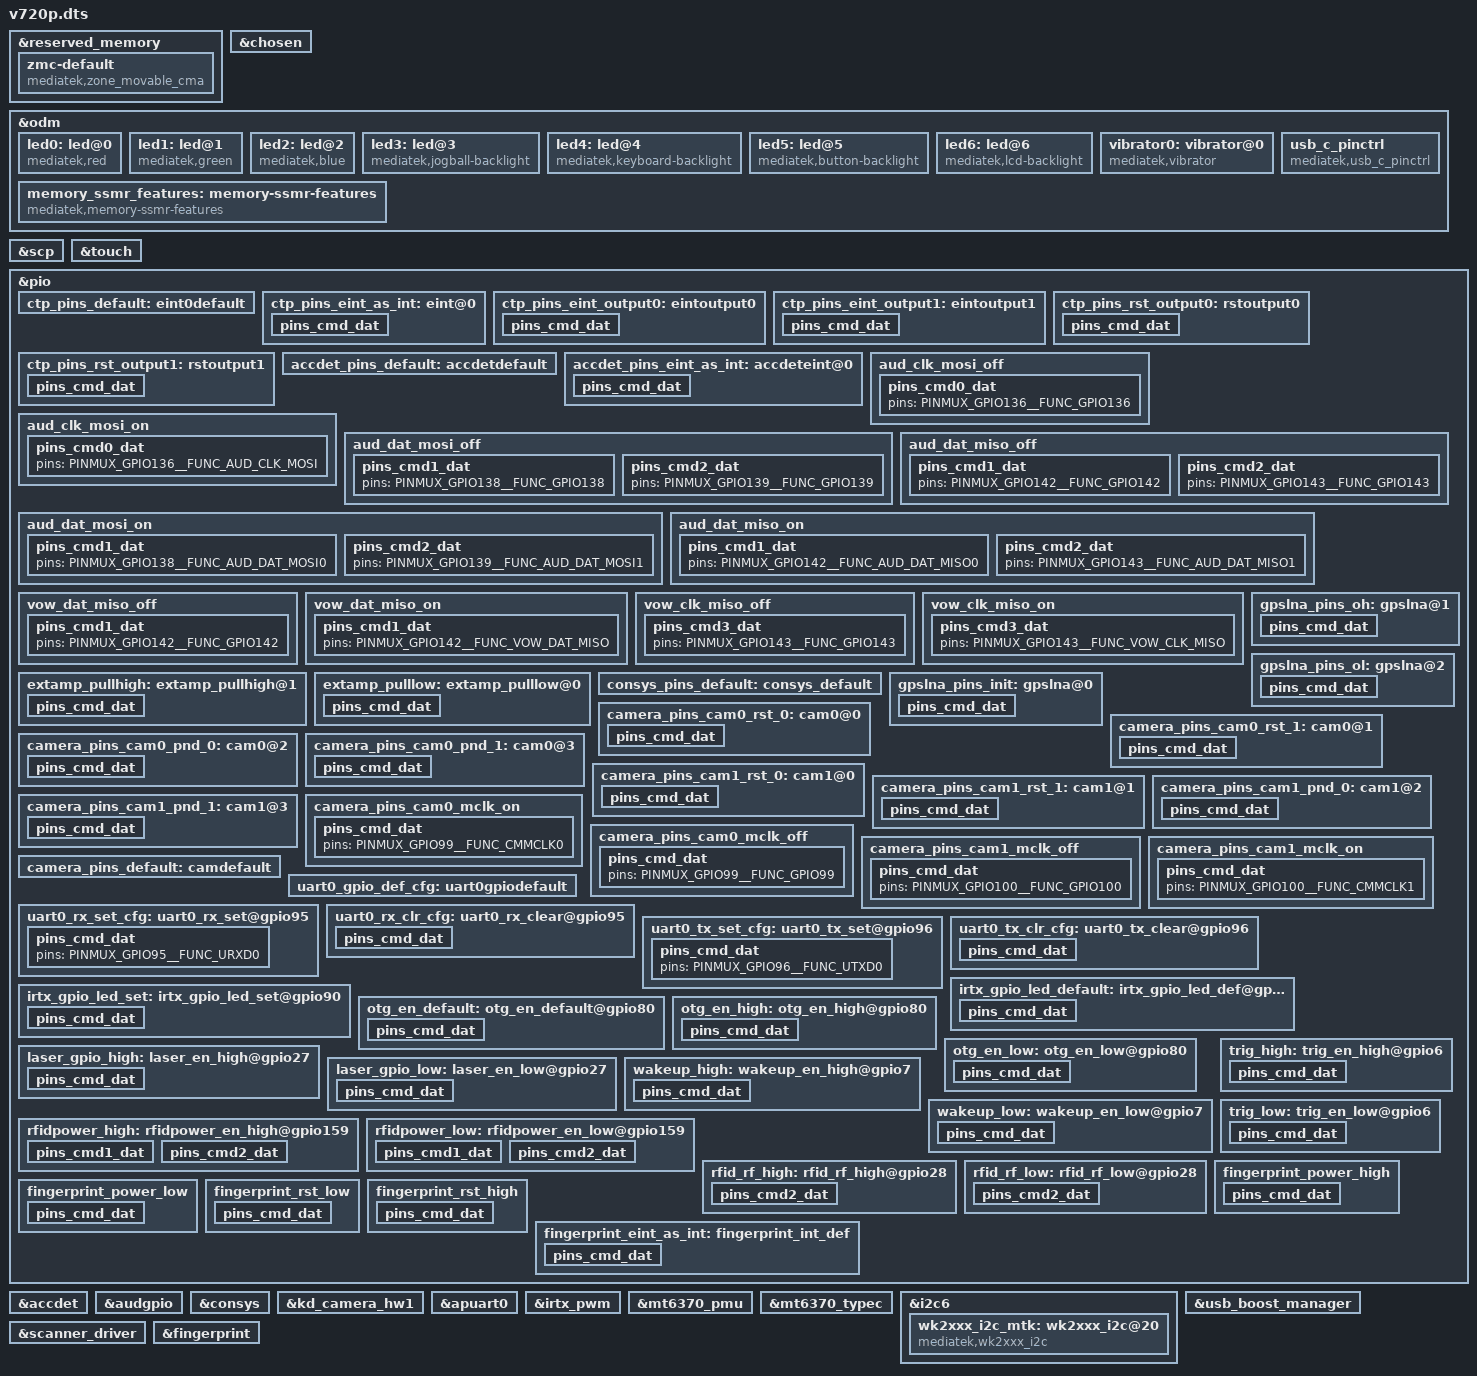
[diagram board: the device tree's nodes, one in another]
/dts-v1/;
/plugin/;
#include <dt-bindings/interrupt-controller/irq.h>
#include <dt-bindings/interrupt-controller/arm-gic.h>
#include <dt-bindings/pinctrl/mt6771-pinfunc.h>

&reserved_memory {
	#address-cells = <2>;
	#size-cells = <2>;
	ranges;

	zmc-default {
		compatible = "mediatek,zone_movable_cma";
		size = <0 0xffc00000>;
		alignment = <0 0x10000000>;
		alloc-ranges = <0 0xc0000000 1 0x00000000>;
	};
};

/* chosen */
&chosen {
	/* fpga may has no lk, we need to specify display info here */
	/* fb buffer is reserved using this dts by memory node above */

	atag,videolfb-fb_base_l = <0x5e605000>;
	atag,videolfb-fb_base_h = <0x0>;
	atag,videolfb-islcmfound = <1>;
	atag,videolfb-islcm_inited = <0>;
	atag,videolfb-fps= <6000>;
	atag,videolfb-vramSize= <0x017bb000>;
	atag,videolfb-lcmname= "nt35595_fhd_dsi_cmd_truly_nt50358_drv";
};

&odm {
	led0:led@0 {
		compatible = "mediatek,red";
		led_mode = <0>;
		data = <1>;
		pwm_config = <0 0 0 0 0>;
	};
	led1:led@1 {
		compatible = "mediatek,green";
		led_mode = <0>;
		data = <1>;
		pwm_config = <0 0 0 0 0>;
	};
	led2:led@2 {
		compatible = "mediatek,blue";
		led_mode = <0>;
		data = <1>;
		pwm_config = <0 0 0 0 0>;
	};
	led3:led@3 {
		compatible = "mediatek,jogball-backlight";
		led_mode = <0>;
		data = <1>;
		pwm_config = <0 0 0 0 0>;
	};
	led4:led@4 {
		compatible = "mediatek,keyboard-backlight";
		led_mode = <0>;
		data = <1>;
		pwm_config = <0 0 0 0 0>;
	};
	led5:led@5 {
		compatible = "mediatek,button-backlight";
		led_mode = <0>;
		data = <1>;
		pwm_config = <0 0 0 0 0>;
	};
	led6:led@6 {
		compatible = "mediatek,lcd-backlight";
		led_mode = <5>;
		data = <1>;
		pwm_config = <0 1 0 0 0>;
	};
	vibrator0:vibrator@0 {
		compatible = "mediatek,vibrator";
		vib_timer = <25>;
		vib_limit = <9>;
		vib_vol= <9>;
	};
	memory_ssmr_features: memory-ssmr-features {
		compatible = "mediatek,memory-ssmr-features";
		svp-size = <0 0>;
		iris-recognition-size = <0 0>;
		2d_fr-size = <0 0>;
		tui-size = <0 0>;
		wfd-size = <0 0>;
		prot-sharedmem-size = <0 0>;
	};
	usb_c_pinctrl:usb_c_pinctrl {
		compatible = "mediatek,usb_c_pinctrl";
	};
};

&scp {
	core_1 = "enable";
	scp_sramSize = <0x00080000>;     /* scp_A_sram_size */
};

/* TOUCH start */
&touch {
	tpd-resolution = <1080 1920>;
	use-tpd-button = <0>;
	tpd-key-num = <3>;
	tpd-key-local= <139 172 158 0>;
	tpd-key-dim-local = <90 883 100 40 230 883 100 40 370 883 100 40 0 0 0 0>;
	tpd-max-touch-num = <5>;
	tpd-filter-enable = <1>;
	tpd-filter-pixel-density = <146>;
	tpd-filter-custom-prameters = <0 0 0 0 0 0 0 0 0 0 0 0>;
	tpd-filter-custom-speed = <0 0 0>;
	pinctrl-names = "default", "state_eint_as_int", "state_eint_output0", "state_eint_output1",
		"state_rst_output0", "state_rst_output1";
	pinctrl-0 = <&ctp_pins_default>;
	pinctrl-1 = <&ctp_pins_eint_as_int>;
	pinctrl-2 = <&ctp_pins_eint_output0>;
	pinctrl-3 = <&ctp_pins_eint_output1>;
	pinctrl-4 = <&ctp_pins_rst_output0>;
	pinctrl-5 = <&ctp_pins_rst_output1>;
	status = "okay";
};
&pio {
	ctp_pins_default: eint0default {
	};
	ctp_pins_eint_as_int: eint@0 {
		pins_cmd_dat {
			pins = <PINMUX_GPIO1__FUNC_GPIO1>;
			slew-rate = <0>;
			bias-disable;
		};
	};
	ctp_pins_eint_output0: eintoutput0 {
		pins_cmd_dat {
			pins = <PINMUX_GPIO1__FUNC_GPIO1>;
			slew-rate = <1>;
			output-low;
		};
	};
	ctp_pins_eint_output1: eintoutput1 {
		pins_cmd_dat {
			pins = <PINMUX_GPIO1__FUNC_GPIO1>;
			slew-rate = <1>;
			output-high;
		};
	};
	ctp_pins_rst_output0: rstoutput0 {
		pins_cmd_dat {
			pins = <PINMUX_GPIO20__FUNC_GPIO20>;
			slew-rate = <1>;
			output-low;
		};
	};
	ctp_pins_rst_output1: rstoutput1 {
		pins_cmd_dat {
			pins = <PINMUX_GPIO20__FUNC_GPIO20>;
			slew-rate = <1>;
			output-high;
		};
	};
};
/* TOUCH end */

/* accdet start */
&accdet {
	/* accdet micbias voltage: 0x07,2.7v;0x05,2.5v;0x02,1.9v */
	accdet-mic-vol = <6>;
	headset-mode-setting = <0x500 0x500 1 0x1f0 0x800 0x800 0x20 0x44>;
	accdet-plugout-debounce = <1>;
	/*1:ACC mode, 2:low cost without in bias, 6:low cost with in bias*/
	accdet-mic-mode = <2>;
	/* eint_level_trigger: 8,LEVEL_LOW(default);4,LEVEL_HIGH;others,LEVEL_LOW */
	headset-eint-level-pol = <8>;
	/*0--MD_MAX--UP_MAX--DW_MAX*/
	headset-three-key-threshold = <0 60 200 400>;
	headset-three-key-threshold-CDD = <0 121 192 600>;
	/*0--MD_MAX--VOICE_MAX--UP_MAX--DW_MAX*/
	headset-four-key-threshold = <0 58 121 192 400>;
	/*moisture external resister ohm*/
	moisture-external-r = <2000000>;
	/*moisture internal resister ohm*/
	moisture-internal-r = <47000>;
	/*moisture of water resister ohm*/
	moisture-water-r = <10000>;
	/* ACCDET GPIO standardization ACC mode no use */
	pinctrl-names = "default", "state_eint_as_int";
	pinctrl-0 = <&accdet_pins_default>;
	pinctrl-1 = <&accdet_pins_eint_as_int>;
	status = "okay";
};
&pio {
	accdet_pins_default: accdetdefault {
	};
	accdet_pins_eint_as_int: accdeteint@0 {
		pins_cmd_dat {
		};
	};
};
/* accdet end */

/* AUDIO GPIO standardization */
&audgpio {
	pinctrl-names = "aud_clk_mosi_off",
			"aud_clk_mosi_on",
			"aud_dat_mosi_off",
			"aud_dat_mosi_on",
			"aud_dat_miso_off",
			"aud_dat_miso_on",
			"vow_dat_miso_off",
			"vow_dat_miso_on",
			"vow_clk_miso_off",
			"vow_clk_miso_on",
            "extamp-pullhigh",
            "extamp-pulllow";
	pinctrl-0 = <&aud_clk_mosi_off>;
	pinctrl-1 = <&aud_clk_mosi_on>;
	pinctrl-2 = <&aud_dat_mosi_off>;
	pinctrl-3 = <&aud_dat_mosi_on>;
	pinctrl-4 = <&aud_dat_miso_off>;
	pinctrl-5 = <&aud_dat_miso_on>;
	pinctrl-6 = <&vow_dat_miso_off>;
	pinctrl-7 = <&vow_dat_miso_on>;
	pinctrl-8 = <&vow_clk_miso_off>;
	pinctrl-9 = <&vow_clk_miso_on>;
	pinctrl-10 = <&extamp_pullhigh>;
	pinctrl-11 = <&extamp_pulllow>;
	status = "okay";
};

&pio {
	aud_clk_mosi_off: aud_clk_mosi_off {
		pins_cmd0_dat {
			pins = <PINMUX_GPIO136__FUNC_GPIO136>;
		};
	};

	aud_clk_mosi_on: aud_clk_mosi_on {
		pins_cmd0_dat {
			pins = <PINMUX_GPIO136__FUNC_AUD_CLK_MOSI>;
		};
	};

	aud_dat_mosi_off: aud_dat_mosi_off {
		pins_cmd1_dat {
			pins = <PINMUX_GPIO138__FUNC_GPIO138>;
		};
		pins_cmd2_dat {
			pins = <PINMUX_GPIO139__FUNC_GPIO139>;
		};
	};

	aud_dat_mosi_on: aud_dat_mosi_on {
		pins_cmd1_dat {
			pins = <PINMUX_GPIO138__FUNC_AUD_DAT_MOSI0>;
		};
		pins_cmd2_dat {
			pins = <PINMUX_GPIO139__FUNC_AUD_DAT_MOSI1>;
		};
	};

	aud_dat_miso_off: aud_dat_miso_off {
		pins_cmd1_dat {
			pins = <PINMUX_GPIO142__FUNC_GPIO142>;
		};
		pins_cmd2_dat {
			pins = <PINMUX_GPIO143__FUNC_GPIO143>;
		};
	};

	aud_dat_miso_on: aud_dat_miso_on {
		pins_cmd1_dat {
			pins = <PINMUX_GPIO142__FUNC_AUD_DAT_MISO0>;
		};
		pins_cmd2_dat {
			pins = <PINMUX_GPIO143__FUNC_AUD_DAT_MISO1>;
		};
	};

	vow_dat_miso_off: vow_dat_miso_off {
		pins_cmd1_dat {
			pins = <PINMUX_GPIO142__FUNC_GPIO142>;
		};
	};

	vow_dat_miso_on: vow_dat_miso_on {
		pins_cmd1_dat {
			pins = <PINMUX_GPIO142__FUNC_VOW_DAT_MISO>;
		};
	};

	vow_clk_miso_off: vow_clk_miso_off {
		pins_cmd3_dat {
			pins = <PINMUX_GPIO143__FUNC_GPIO143>;
		};
	};

	vow_clk_miso_on: vow_clk_miso_on {
		pins_cmd3_dat {
			pins = <PINMUX_GPIO143__FUNC_VOW_CLK_MISO>;
		};
	};
	extamp_pullhigh: extamp_pullhigh@1 {
		pins_cmd_dat {
			pins = <PINMUX_GPIO153__FUNC_GPIO153>;
			slew-rate = <1>;
			output-high;
		};
	};
	extamp_pulllow: extamp_pulllow@0 {
		pins_cmd_dat {
			pins = <PINMUX_GPIO153__FUNC_GPIO153>;
			slew-rate = <1>;
			output-low;
		};
	};
};
/* AUDIO end */

/* CONSYS GPIO standardization */
&pio {
	consys_pins_default: consys_default {
	};
	gpslna_pins_init: gpslna@0 {
		pins_cmd_dat {
			pins = <PINMUX_GPIO155__FUNC_GPIO155>;
			slew-rate = <0>;
			bias-disable;
			output-low;
		};
	};
	gpslna_pins_oh: gpslna@1 {
		pins_cmd_dat {
			pins = <PINMUX_GPIO155__FUNC_GPIO155>;
			slew-rate = <1>;
			output-high;
		};
	};
	gpslna_pins_ol: gpslna@2 {
		pins_cmd_dat {
			pins = <PINMUX_GPIO155__FUNC_GPIO155>;
			slew-rate = <1>;
			output-low;
		};
	};
};
&consys {
	pinctrl-names = "default", "gps_lna_state_init", "gps_lna_state_oh", "gps_lna_state_ol";
	pinctrl-0 = <&consys_pins_default>;
	pinctrl-1 = <&gpslna_pins_init>;
	pinctrl-2 = <&gpslna_pins_oh>;
	pinctrl-3 = <&gpslna_pins_ol>;
	status = "okay";
};
/* CONSYS end */

/* CAMERA GPIO standardization */
&pio {
	camera_pins_cam0_rst_0: cam0@0 {
		pins_cmd_dat {
			pins = <PINMUX_GPIO101__FUNC_GPIO101>;
			slew-rate = <1>; /*direction 0:in, 1:out*/
			output-low;/*direction out used only. output_low or high*/
		};
	};
	camera_pins_cam0_rst_1: cam0@1 {
		pins_cmd_dat {
			pins = <PINMUX_GPIO101__FUNC_GPIO101>;
			slew-rate = <1>;
			output-high;
		};
	};
	camera_pins_cam0_pnd_0: cam0@2 {
		pins_cmd_dat {
			pins = <PINMUX_GPIO97__FUNC_GPIO97>;
			slew-rate = <1>;
			output-low;
		};
	};
	camera_pins_cam0_pnd_1: cam0@3 {
		pins_cmd_dat {
			pins = <PINMUX_GPIO97__FUNC_GPIO97>;
			slew-rate = <1>;
			output-high;
		};
	};
	camera_pins_cam1_rst_0: cam1@0 {
		pins_cmd_dat {
			pins = <PINMUX_GPIO102__FUNC_GPIO102>;
			slew-rate = <1>; /*direction 0:in, 1:out*/
			output-low;/*direction out used only. output_low or high*/
		};
	};
	camera_pins_cam1_rst_1: cam1@1 {
		pins_cmd_dat {
			pins = <PINMUX_GPIO102__FUNC_GPIO102>;
			slew-rate = <1>;
			output-high;
		};
	};
	camera_pins_cam1_pnd_0: cam1@2 {
		pins_cmd_dat {
			pins = <PINMUX_GPIO98__FUNC_GPIO98>;
			slew-rate = <1>;
			output-low;
		};
	};
	camera_pins_cam1_pnd_1: cam1@3 {
		pins_cmd_dat {
			pins = <PINMUX_GPIO98__FUNC_GPIO98>;
			slew-rate = <1>;
			output-high;
		};
	};
	camera_pins_cam0_mclk_on: camera_pins_cam0_mclk_on {
		pins_cmd_dat {
			pins = <PINMUX_GPIO99__FUNC_CMMCLK0>;
		};
	};
	camera_pins_cam0_mclk_off: camera_pins_cam0_mclk_off {
		pins_cmd_dat {
			pins = <PINMUX_GPIO99__FUNC_GPIO99>;
		};
	};
	camera_pins_cam1_mclk_off: camera_pins_cam1_mclk_off {
		pins_cmd_dat {
			pins = <PINMUX_GPIO100__FUNC_GPIO100>;
		};
	};
	camera_pins_cam1_mclk_on: camera_pins_cam1_mclk_on {
		pins_cmd_dat {
			pins = <PINMUX_GPIO100__FUNC_CMMCLK1>;
		};
	};
	camera_pins_default: camdefault {
	};
};
&kd_camera_hw1 {
	pinctrl-names = "default",
			"cam0_rst0", "cam0_rst1",
			"cam0_pnd0", "cam0_pnd1",
			"cam1_rst0", "cam1_rst1",
			"cam1_pnd0", "cam1_pnd1",
			"cam0_mclk_off", "cam0_mclk_on",
			"cam1_mclk_off", "cam1_mclk_on";
	pinctrl-0 = <&camera_pins_default>;
	pinctrl-1 = <&camera_pins_cam0_rst_0>;
	pinctrl-2 = <&camera_pins_cam0_rst_1>;
	pinctrl-3 = <&camera_pins_cam0_pnd_0>;
	pinctrl-4 = <&camera_pins_cam0_pnd_1>;
	pinctrl-5 = <&camera_pins_cam1_rst_0>;
	pinctrl-6 = <&camera_pins_cam1_rst_1>;
	pinctrl-7 = <&camera_pins_cam1_pnd_0>;
	pinctrl-8 = <&camera_pins_cam1_pnd_1>;
	pinctrl-9 = <&camera_pins_cam0_mclk_off>;
	pinctrl-10 = <&camera_pins_cam0_mclk_on>;
	pinctrl-11 = <&camera_pins_cam1_mclk_off>;
	pinctrl-12 = <&camera_pins_cam1_mclk_on>;
	status = "okay";
};

/* UART GPIO */
&apuart0 {
	pinctrl-names = "uart0_gpio_default",
			"uart0_rx_set",
			"uart0_rx_clear",
			"uart0_tx_set",
			"uart0_tx_clear";
	pinctrl-0 = <&uart0_gpio_def_cfg>;
	pinctrl-1 = <&uart0_rx_set_cfg>;
	pinctrl-2 = <&uart0_rx_clr_cfg>;
	pinctrl-3 = <&uart0_tx_set_cfg>;
	pinctrl-4 = <&uart0_tx_clr_cfg>;
	status = "okay";
};

&pio {
	/* UART GPIO Settings - Start */
	/* UART0: rx set, rx clear, tx clear, tx clear*/
	uart0_gpio_def_cfg:uart0gpiodefault {

	};
	uart0_rx_set_cfg:uart0_rx_set@gpio95 {
		pins_cmd_dat {
			pins = <PINMUX_GPIO95__FUNC_URXD0>;
		};
	};
	uart0_rx_clr_cfg:uart0_rx_clear@gpio95 {
		pins_cmd_dat {
			pins = <PINMUX_GPIO95__FUNC_GPIO95>;
			slew-rate = <1>;
			output-high;
		};
	};
	uart0_tx_set_cfg:uart0_tx_set@gpio96 {
		pins_cmd_dat {
			pins = <PINMUX_GPIO96__FUNC_UTXD0>;
		};
	};
	uart0_tx_clr_cfg:uart0_tx_clear@gpio96 {
		pins_cmd_dat {
			pins = <PINMUX_GPIO96__FUNC_GPIO96>;
			slew-rate = <1>;
			output-high;
		};
	};
};/* UART GPIO end */

/* IRTX GPIO Start */
&irtx_pwm {
	pinctrl-names = "irtx_gpio_led_default", "irtx_gpio_led_set";
	pinctrl-0 = <&irtx_gpio_led_default>;
	pinctrl-1 = <&irtx_gpio_led_set>;
	status = "okay";
};
&pio {
	/* IRTX GPIO Settings -Start */
	/* default: GPIO0, output, high */
	irtx_gpio_led_default:irtx_gpio_led_def@gpio90 {
		pins_cmd_dat {
			pins = <PINMUX_GPIO90__FUNC_GPIO90>;
			slew-rate = <1>;
			bias-disable;
			output-low;
			input-schmitt-enable = <0>;
		};
	};

	irtx_gpio_led_set:irtx_gpio_led_set@gpio90 {
		pins_cmd_dat {
			pins = <PINMUX_GPIO90__FUNC_PWM_A>;
			slew-rate = <1>;
			output-high;
		};
	};
}; /* IRTX GPIO Settings -End */

&mt6370_pmu {
	mt6370,intr_gpio_num = <10>; /* direct defined GPIO num */
	mt6370,intr_gpio = <&pio 10 0x0>;
};

&mt6370_typec {
	mt6370pd,intr_gpio_num = <41>; /* direct defined GPIO num */
	mt6370pd,intr_gpio = <&pio 41 0x0>;
};
&i2c6 {
    wk2xxx_i2c_mtk:wk2xxx_i2c@20 {
        compatible = "mediatek,wk2xxx_i2c";
        reg = <0x20>;
        status = "okay";
        gpio-ls = <55>;
        gpio-ls-std = <&pio 55 0x0>;
        gpio-power = <57>;
        gpio-power-std = <&pio 57 0x0>;
        gpio-rst = <78>;
        gpio-rst-std = <&pio 78 0x0>;
        gpio-irq = <56>;
        gpio-irq-std = <&pio 56 0x0>;
    };
};

/* usb_boost_manager otg_en Start */
&usb_boost_manager {
	pinctrl-names = "otg_en_default", "otg_en_high", "otg_en_low";
	pinctrl-0 = <&otg_en_default>;
	pinctrl-1 = <&otg_en_high>;
	pinctrl-2 = <&otg_en_low>;
	status = "okay";
};
&pio {
	otg_en_default:otg_en_default@gpio80 {
		pins_cmd_dat {
			pins = <PINMUX_GPIO80__FUNC_GPIO80>;
			slew-rate = <1>;
			output-low;
		};
	};

	otg_en_high:otg_en_high@gpio80 {
		pins_cmd_dat {
			pins = <PINMUX_GPIO80__FUNC_GPIO80>;
			slew-rate = <1>;
			output-high;
		};
	};

	otg_en_low:otg_en_low@gpio80 {
		pins_cmd_dat {
			pins = <PINMUX_GPIO80__FUNC_GPIO80>;
			slew-rate = <1>;
			output-low;
		};
	};
}; /* usb_boost_manager otg_en Settings -End */
&scanner_driver{
	pinctrl-names = "laser_gpio_high","laser_gpio_low","wakeup_high","wakeup_low","trig_high","trig_low","rfid_power_high","rfid_power_low","rfid_rf_high","rfid_rf_low";
	pinctrl-0 = <&laser_gpio_high>;
	pinctrl-1 = <&laser_gpio_low>;
	pinctrl-2 = <&wakeup_high>;
	pinctrl-3 = <&wakeup_low>;
	pinctrl-4 = <&trig_high>;
	pinctrl-5 = <&trig_low>;
	pinctrl-6 = <&rfidpower_high>;
	pinctrl-7 = <&rfidpower_low>;
	pinctrl-8 = <&rfid_rf_high>;
	pinctrl-9 = <&rfid_rf_low>;
	status = "okay";
};
&pio {
	laser_gpio_high:laser_en_high@gpio27 {
		pins_cmd_dat {
			pins = <PINMUX_GPIO27__FUNC_GPIO27>;
			slew-rate = <1>;
			output-high;
		};
	};
	laser_gpio_low:laser_en_low@gpio27 {
		pins_cmd_dat {
			pins = <PINMUX_GPIO27__FUNC_GPIO27>;
			slew-rate = <1>;
			output-low;
		};
	};
	wakeup_high:wakeup_en_high@gpio7 {
		pins_cmd_dat {
			pins = <PINMUX_GPIO7__FUNC_GPIO7>;
			slew-rate = <1>;
			output-high;
		};
	};
	wakeup_low:wakeup_en_low@gpio7 {
		pins_cmd_dat {
			pins = <PINMUX_GPIO7__FUNC_GPIO7>;
			slew-rate = <1>;
			output-low;
		};
	};
	trig_high:trig_en_high@gpio6 {
		pins_cmd_dat {
			pins = <PINMUX_GPIO6__FUNC_GPIO6>;
			slew-rate = <1>;
			output-high;
		};
	};
	trig_low:trig_en_low@gpio6 {
		pins_cmd_dat {
			pins = <PINMUX_GPIO6__FUNC_GPIO6>;
			slew-rate = <1>;
			output-low;
		};
	};
	rfidpower_high:rfidpower_en_high@gpio159 {
		pins_cmd1_dat {
			pins = <PINMUX_GPIO159__FUNC_GPIO159>;
			slew-rate = <1>;
			output-high;
		};
		pins_cmd2_dat {
			pins = <PINMUX_GPIO177__FUNC_GPIO177>;
			slew-rate = <1>;
			output-high;
		};
	};
	rfidpower_low:rfidpower_en_low@gpio159 {
		pins_cmd1_dat {
			pins = <PINMUX_GPIO159__FUNC_GPIO159>;
			slew-rate = <1>;
			output-low;
		};
		pins_cmd2_dat {
			pins = <PINMUX_GPIO177__FUNC_GPIO177>;
			slew-rate = <1>;
			output-low;
		};
	};
	rfid_rf_high:rfid_rf_high@gpio28 {
		pins_cmd2_dat {
			pins = <PINMUX_GPIO28__FUNC_GPIO28>;
			slew-rate = <1>;
			output-high;
		};
	};
	rfid_rf_low:rfid_rf_low@gpio28 {
		pins_cmd2_dat {
			pins = <PINMUX_GPIO28__FUNC_GPIO28>;
			slew-rate = <1>;
			output-low;
		};
	};
};
/* sunwave fingerprint start */
&pio {
    fingerprint_power_high:fingerprint_power_high{
        pins_cmd_dat {
            pins = <PINMUX_GPIO22__FUNC_GPIO22>;
            slew-rate = <1>;
            output-high;
        };
    };
    fingerprint_power_low:fingerprint_power_low{
        pins_cmd_dat {
            pins = <PINMUX_GPIO22__FUNC_GPIO22>;
            slew-rate = <1>;
            output-high;
        };
    };
    fingerprint_rst_low:fingerprint_rst_low{
        pins_cmd_dat {
            pins = <PINMUX_GPIO160__FUNC_GPIO160>;
            slew-rate = <1>;
            output-low;
        };
    };
    fingerprint_rst_high:fingerprint_rst_high{
        pins_cmd_dat {
            pins = <PINMUX_GPIO160__FUNC_GPIO160>;
            slew-rate = <1>;
            output-high;
        };
    };
    fingerprint_eint_as_int:fingerprint_int_def{
        pins_cmd_dat {
            pins = <PINMUX_GPIO166__FUNC_GPIO166>;
            slew-rate = <0>;
            bias-pull-down = <00>;
        };
    };
};

&fingerprint{
    pinctrl-names = "finger_power_high", "finger_power_low", "finger_rst_low", "finger_rst_high", "eint_as_int";
    pinctrl-0 = <&fingerprint_power_high>;
    pinctrl-1 = <&fingerprint_power_low>;
    pinctrl-2 = <&fingerprint_rst_low>;
    pinctrl-3 = <&fingerprint_rst_high>;
    pinctrl-4 = <&fingerprint_eint_as_int>;
    irq_gpio = <&pio 166 0>;
    status = "okay";
};
/* sunwave fingerprint end */

#include <v720p/cust.dtsi>
/*End of this file, DO NOT ADD ANYTHING HERE*/


